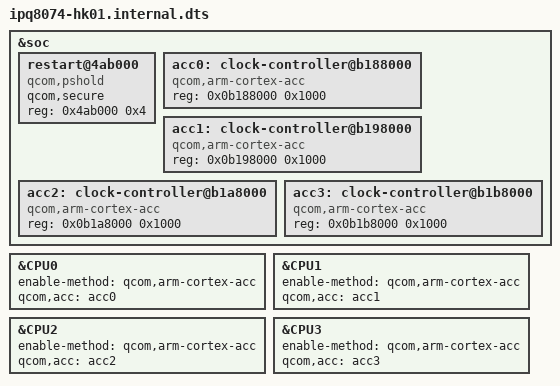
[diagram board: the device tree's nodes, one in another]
/*
 * Copyright (c) 2017, 2020, The Linux Foundation. All rights reserved.
 *
 * Permission to use, copy, modify, and/or distribute this software for any
 * purpose with or without fee is hereby granted, provided that the above
 * copyright notice and this permission notice appear in all copies.
 *
 * THE SOFTWARE IS PROVIDED "AS IS" AND THE AUTHOR DISCLAIMS ALL WARRANTIES
 * WITH REGARD TO THIS SOFTWARE INCLUDING ALL IMPLIED WARRANTIES OF
 * MERCHANTABILITY AND FITNESS. IN NO EVENT SHALL THE AUTHOR BE LIABLE FOR
 * ANY SPECIAL, DIRECT, INDIRECT, OR CONSEQUENTIAL DAMAGES OR ANY DAMAGES
 * WHATSOEVER RESULTING FROM LOSS OF USE, DATA OR PROFITS, WHETHER IN AN
 * ACTION OF CONTRACT, NEGLIGENCE OR OTHER TORTIOUS ACTION, ARISING OUT OF
 * OR IN CONNECTION WITH THE USE OR PERFORMANCE OF THIS SOFTWARE.
 */
#include "ipq8074-hk01.dts"

/ {
	/delete-node/ psci;
};

&soc {
	restart@4ab000 {
		compatible = "qcom,pshold";
		qcom,secure;
		reg = <0x4ab000 0x4>;
	};

	acc0: clock-controller@b188000 {
		compatible = "qcom,arm-cortex-acc";
		reg = <0x0b188000 0x1000>;
	};

	acc1: clock-controller@b198000 {
		compatible = "qcom,arm-cortex-acc";
		reg = <0x0b198000 0x1000>;
	};

	acc2: clock-controller@b1a8000 {
		compatible = "qcom,arm-cortex-acc";
		reg = <0x0b1a8000 0x1000>;
	};

	acc3: clock-controller@b1b8000 {
		compatible = "qcom,arm-cortex-acc";
		reg = <0x0b1b8000 0x1000>;
	};
};

&CPU0 {
	enable-method = "qcom,arm-cortex-acc";
	qcom,acc = <&acc0>;
};

&CPU1 {
	enable-method = "qcom,arm-cortex-acc";
	qcom,acc = <&acc1>;
};

&CPU2 {
	enable-method = "qcom,arm-cortex-acc";
	qcom,acc = <&acc2>;
};

&CPU3 {
	enable-method = "qcom,arm-cortex-acc";
	qcom,acc = <&acc3>;
};
